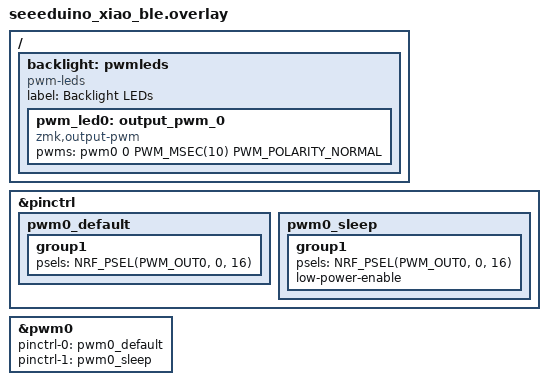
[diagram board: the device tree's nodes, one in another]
&pinctrl {
    pwm0_default: pwm0_default {
        group1 {
            psels = <NRF_PSEL(PWM_OUT0, 0, 16)>;
        };
    };
    pwm0_sleep: pwm0_sleep {
        group1 {
            psels = <NRF_PSEL(PWM_OUT0, 0, 16)>;
            low-power-enable;
        };
    };
};

/ {
    
    backlight: pwmleds {
        compatible = "pwm-leds";
        label = "Backlight LEDs";
        /* setup wired PWM device to control a LED */
        pwm_led0: output_pwm_0 {
            compatible = "zmk,output-pwm";
            #binding-cells = <0>;
            pwms = <&pwm0 0 PWM_MSEC(10) PWM_POLARITY_NORMAL>;
        };
        // pwm_led_0: pwm_led_0 {
        //     pwms = <&pwm0 0 PWM_MSEC(10) PWM_POLARITY_NORMAL>;
        // };
    };
};

&pwm0 {
    status = "okay";
    pinctrl-0 = <&pwm0_default>;
    pinctrl-1 = <&pwm0_sleep>;
    pinctrl-names = "default", "sleep";
};

// /
//     chosen {
//         zmk,backlight = &backlight;
//     };
// };
